# LIFCL_33U register map
Vendor: Latticsemi.com; Series: LIFCL; File version: 1.0
Registers are 32-bit, read-write, reset 0x0 unless marked. A register's access mark holds for its fields unless they carry their own. Offsets are from the block's base; [hi:lo] are bit positions.

## lsc_i2cc_inst
Base 0x00050C00
0x00 WR_DATA_REG wo — Write Data Register
  [7:0] tx_fifo — Write access to this field pushes data to Transmit FIFO
0x00 RD_DATA_REG ro — Read Data Register
  [7:0] rx_fifo — Read access to this field pops data from Receive FIFO
0x04 TARGET_ADDRL_REG — Lower 7-bit target address
  [6:0] target_addr_l_reg
0x08 TARGET_ADDRH_REG — Upper 3-bit target address
  [2:0] target_addr_h_reg — For 10-bit address mode only. Lower 3-bit target address
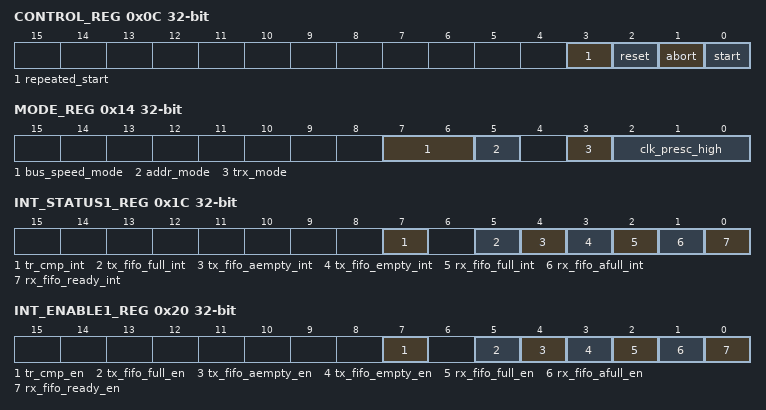
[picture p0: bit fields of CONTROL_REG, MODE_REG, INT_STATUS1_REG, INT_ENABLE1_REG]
0x0C CONTROL_REG wo — Control Register
  [3] repeated_start — Causes I2C controller to omit the generation of a stop condition following the completion of a transaction. Subsequent transaction will be a repeated start.
  [2] reset — Set this bit to 1 to reset this I2C Controller
  [1] abort — Stops an I2C transaction currently in progress
  [0] start — Starts the I2C transaction. This is asserted after the MPU has finished writing to all configuration registers
0x10 TGT_BYTE_CNT_REG — Target Byte Count Register
  [7:0] byte_cnt — Number of data bytes for the current transaction
0x14 MODE_REG — Mode Register
  [7:6] bus_speed_mode — Selects setup time for Repeated START Condition and setup time for STOP Condition
  [5] addr_mode — Selects the addressing mode either 7 or 10 bits
  [3] trx_mode — Sets the read or write operation on the I2C bus
  [2:0] clk_presc_high — The upper three bits of the clock prescaler
0x18 CLK_PRESCL_REG — Clock Prescaler Register Low Bits
  [7:0] clk_presc_low — Lower 8-bit value of divisor in clock prescaler register
0x1C INT_STATUS1_REG — Interrupt Status 1st Register
  [7] tr_cmp_int — This interrupt status bit asserts when the number of transmitted words via SPI interface reaches the TGT_WORD_CNT_REG.target_word_cnt setting value.
  [5] tx_fifo_full_int — This interrupt status bit asserts when Transmit FIFO changes from not full state to full state.
  [4] tx_fifo_aempty_int — This interrupt status bit asserts when the amount of data words in Transmit FIFO changes from 'TX FIFO Almost Empty Flag' + 1 to 'TX FIFO Almost Empty Flag'.
  [3] tx_fifo_empty_int — This interrupt status bit asserts when the last data in Transmit FIFO is popped-out, causing the FIFO to become empty.
  [2] rx_fifo_full_int — This interrupt status bit asserts when RX FIFO full status changes from not full to full state.
  [1] rx_fifo_afull_int — This interrupt status bit asserts when the amount of data words in Receive FIFO changes from 'RX FIFO Almost Full Flag' - 1 to 'RX FIFO Almost Full Flag'.
  [0] rx_fifo_ready_int — This interrupt status bit asserts when Receive FIFO is empty and receives a data word from SPI interface.
0x20 INT_ENABLE1_REG — Interrupt Enable 1st Register
  [7] tr_cmp_en — Interrupt enabled bit corresponded to Transfer Complete Interrupt Status.
  [5] tx_fifo_full_en — Interrupt enabled bit corresponded to Transmit FIFO Full Interrupt Status.
  [4] tx_fifo_aempty_en — Interrupt enabled bit corresponded to Transmit FIFO Almost Empty Interrupt Status.
  [3] tx_fifo_empty_en — Interrupt enabled bit corresponded to Transmit FIFO Empty Interrupt Status.
  [2] rx_fifo_full_en — Interrupt enabled bit corresponded to Receive FIFO Full Interrupt Status.
  [1] rx_fifo_afull_en — Interrupt enabled bit corresponded to Receive FIFO Almost Full Interrupt Status.
  [0] rx_fifo_ready_en — Interrupt enabled bit corresponded to Receive FIFO Ready Interrupt Status.
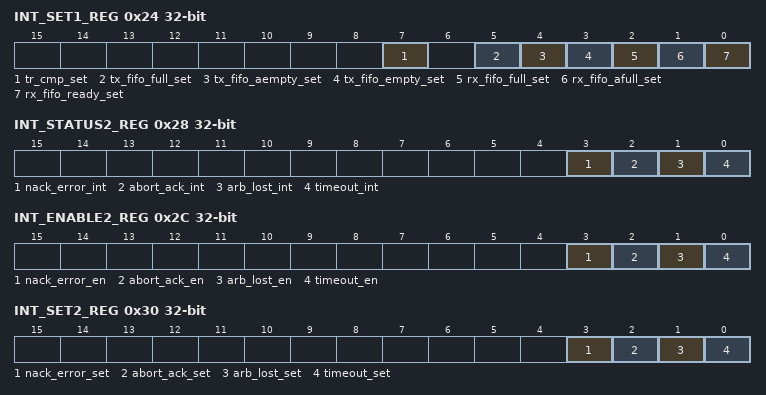
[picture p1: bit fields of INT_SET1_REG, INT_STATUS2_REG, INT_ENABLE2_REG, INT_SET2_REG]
0x24 INT_SET1_REG wo — Interrupt Set 1st Register
  [7] tr_cmp_set — Interrupt set bit corresponded to Transfer Complete Interrupt Status.
  [5] tx_fifo_full_set — Interrupt set bit corresponded to Transmit FIFO Full Interrupt Status.
  [4] tx_fifo_aempty_set — Interrupt set bit corresponded to Transmit FIFO Almost Empty Interrupt Status.
  [3] tx_fifo_empty_set — Interrupt set bit corresponded to Transmit FIFO Empty Interrupt Status.
  [2] rx_fifo_full_set — Interrupt set bit corresponded to Receive FIFO Full Interrupt Status.
  [1] rx_fifo_afull_set — Interrupt set bit corresponded to Receive FIFO Almost Full Interrupt Status.
  [0] rx_fifo_ready_set — Interrupt set bit corresponded to Receive FIFO Ready Interrupt Status.
0x28 INT_STATUS2_REG — Interrupt Status 2nd Register
  [3] nack_error_int — This interrupt status bit asserts when NACK is received when expecting an ACK during data phase and address phase.
  [2] abort_ack_int — This interrupt status bit asserts when an I2C Controller IP Core aborts an ongoing transaction because the host writes 1'b1 to CONTROL_REG.abort.
  [1] arb_lost_int — This interrupt status bit asserts when I2C Controller IP Core loses arbitration.
  [0] timeout_int — This interrupt status of bit asserts when scl_io is hold for SCL_TIMEOUT_REG.timeout_val times the programmed SCL low period.
0x2C INT_ENABLE2_REG — Interrupt Enable 2nd Register
  [3] nack_error_en — Defines the interrupt enable bit corresponding to NACK Error Interrupt.
  [2] abort_ack_en — Defines the interrupt enable bit corresponding to Transaction Abort Acknowledgement Interrupt.
  [1] arb_lost_en — Defines the interrupt enable bit corresponding to Arbitration Lost Interrupt.
  [0] timeout_en — Defines the Interrupt enable of bit corresponding to SCL Timeout Interrupt.
0x30 INT_SET2_REG wo — Interrupt Set 2nd Register
  [3] nack_error_set — Defines the interrupt set bit corresponding to NACK Error Interrupt.
  [2] abort_ack_set — Defines the interrupt set bit corresponding to Transaction Abort Acknowledgement Interrupt.
  [1] arb_lost_set — Defines the interrupt set bit corresponding to Arbitration Lost Interrupt.
  [0] timeout_set — Defines the Interrupt set of bit corresponding to SCL Timeout Interrupt.
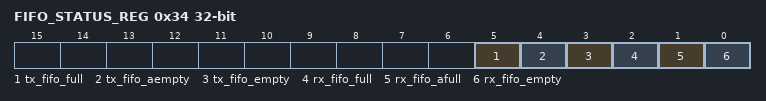
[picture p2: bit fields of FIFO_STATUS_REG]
0x34 FIFO_STATUS_REG ro — FIFO Status Register
  [5] tx_fifo_full — This bit reflects the full condition of Transmit FIFO.
  [4] tx_fifo_aempty — This bit reflects the almost empty condition of Transmit FIFO.
  [3] tx_fifo_empty — This bit reflects the empty condition of Transmit FIFO.
  [2] rx_fifo_full — This bit reflects the full condition of Receive FIFO.
  [1] rx_fifo_afull — This bit reflects the almost full condition of Receive FIFO.
  [0] rx_fifo_empty — This bit reflects the empty condition of Receive FIFO.
0x38 SCL_TIMEOUT_REG — SLC Timeout Register specifies the timeout value for SCL Timeout.
  [7:0] timeout_val — Specifies the timeout value for SCL timeout

## uart0_inst
Base 0x00050000
0x00 THR wo — Transmitter Holding Register is the interface to the Transmitter Buffer/FIFO (XMIT FIFO).
  [7:0] XMIT_FIFO — Write access to this field pushes data to XMIT FIFO
0x00 RBR ro — Receive Buffer Register is the interface to the Receiver Buffer/FIFO (RCVR FIFO).
  [7:0] RCVR_FIFO — Read access to this field pops data from RCVR FIFO
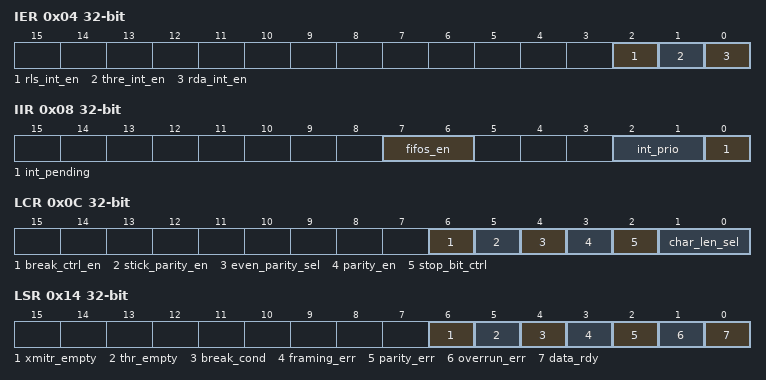
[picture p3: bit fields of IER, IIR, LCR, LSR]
0x04 IER — Interrupt Enable Register enables the four types of UART interrupts.
  [2] rls_int_en — Receiver Line Status Interrupt Enable. 0-> Interrupt is disabled. 1-> Interrupt is enabled.
  [1] thre_int_en — Transmitter Holding Register Empty Interrupt Enable. 0-> Interrupt is disabled. 1-> Interrupt is enabled.
  [0] rda_int_en — Received Data Available Interrupt Enable. 0-> Interrupt is disabled. 1-> Interrupt is enabled.
0x08 IIR ro — Interrupt Identification Register determines the asserted interrupt based on priority.
  [7:6] fifos_en — FIFO mode - Fixed to logic 2'b11. Non-FIFO mode - fixed to 2'b00.
  [2:1] int_prio — 2'b11 -> Receiver Line Status Interrupt. 2'b10 -> Received Data Available Interrupt. 2'b01 -> Transmitter Holding Register Empty Interrupt. 2'b00 -> MODEM Status Interrupt.
  [0] int_pending — 0 -> Interrupt is pending according to int_prio and timeout_int. 1 -> No pending interrupt.
0x0C LCR — Line Control Register configures character length, number stop bits and parity bit.
  [6] break_ctrl_en — Break Control Enable. 0 -> Break control is disabled. 1 -> Break control is enabled.
  [5] stick_parity_en — Stick Parity Enable. 0 -> Stick parity is disabled. 1 -> Stick parity is enabled.
  [4] even_parity_sel — Even Parity Select. 0 -> Odd parity. 1 -> Even Parity.
  [3] parity_en — Parity Enable. 0-> Parity generation and checking is disabled. 1-> Parity generation and checking is enabled.
  [2] stop_bit_ctrl — 0 -> One stop bit is generated in the transmitted data. 1 -> Two stop bits are generated.
  [1:0] char_len_sel — 2'b00 -> 5 bits. 2'b01 -> 6 bits. 2'b10 -> 7 bits. 2'b11 -> 8 bits.
0x14 LSR ro — Line Status Register
  [6] xmitr_empty — Transmitter Empty bit asserts when both XMIT FIFO and Transmitter Shift Register are empty.
  [5] thr_empty — THR Empty bit asserts when XMIT FIFO is empty.
  [4] break_cond — Break condition indicator asserts when rxd_i is held low for longer than full RX time.
  [3] framing_err — Framing Error Indicator asserts when received data does not have a valid stop bit.
  [2] parity_err — Parity Error Indicator asserts when parity error occurs.
  [1] overrun_err — Overrun Error Indicator asserts when RCVR FIFO is full and the next character has been fully received.
  [0] data_rdy — Data Ready Indicator asserts when RCVR FIFO has data.
0x20 DLAB_LSB — Divisor Latch Register LSB
  [7:0] divisor_lsb — The lower byte of the Divisor Latch Register.
0x24 DLAB_MSB — Divisor Latch Register MSB
  [7:0] divisor_msb — The upper byte of the Divisor Latch Register.
